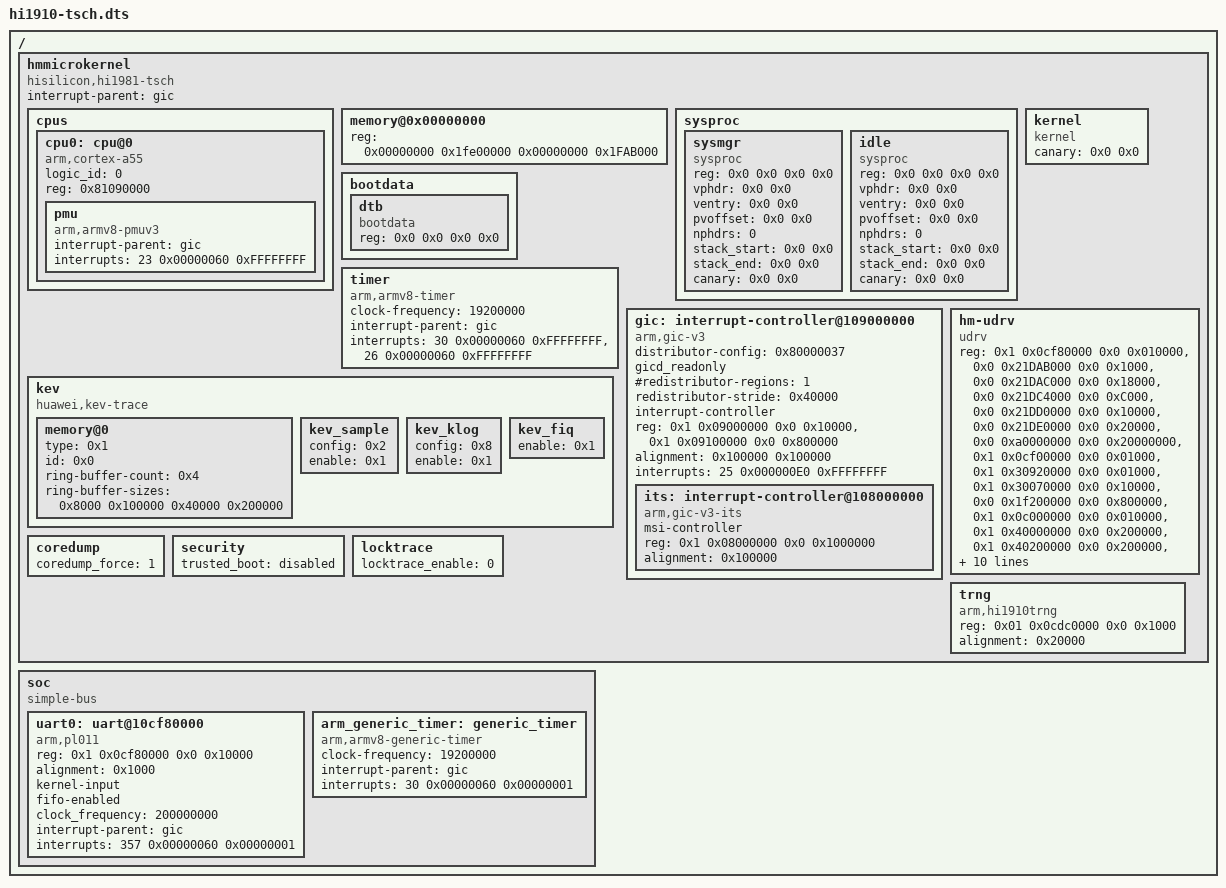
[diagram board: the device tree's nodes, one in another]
/dts-v1/;
/ { #address-cells = <2>; #size-cells = <2>; hmmicrokernel {
	compatible = "hisilicon,hi1981-tsch";
	interrupt-parent = <&gic>;
	#address-cells = <2>;
	#size-cells = <2>;

	cpus {
		#address-cells = <1>;
		#size-cells = <0>;
		cpu0: cpu@0 {
			compatible = "arm,cortex-a55", "arm,armv8";
			device_type = "cpu";
			logic_id = <0>;
			reg = <0x81090000>;
			pmu {
				compatible = "arm,armv8-pmuv3";
				interrupt-parent = <&gic>;
				/* PPI 23: PMUIRQ, level triggered, hwprio:0x60 */
				interrupts = <23 0x00000060 0xFFFFFFFF>;
			};

		};
	};

	memory@0x00000000 {
		device_type = "memory";
		reg = <0x00000000 0x1fe00000 0x00000000 0x1FAB000>;
	};

	sysproc {
		#address-cells = <2>;
		#size-cells = <2>;
		sysmgr {
			compatible = "sysproc", "sysmgr";
			/* filled by bootloader */
			reg      = <0x0 0x0 0x0 0x0>;
			vphdr    = <0x0 0x0>;
			ventry   = <0x0 0x0>;
			pvoffset = <0x0 0x0>;
			nphdrs   = <0>;
			stack_start = <0x0 0x0>;
			stack_end = <0x0 0x0>;
			canary = <0x0 0x0>;
		};

		idle {
			compatible = "sysproc", "idle";
			/* filled by bootloader */
			reg      = <0x0 0x0 0x0 0x0>;
			vphdr    = <0x0 0x0>;
			ventry   = <0x0 0x0>;
			pvoffset = <0x0 0x0>;
			nphdrs   = <0>;
			stack_start = <0x0 0x0>;
			stack_end = <0x0 0x0>;
			canary = <0x0 0x0>;
		};
	};

	kernel {
		compatible = "kernel";
		/* filled by bootloader */
		canary = <0x0 0x0>;
	};

	bootdata {
		#address-cells = <2>;
		#size-cells = <2>;
		dtb {
			compatible = "bootdata", "dtb";
			/* filled by bootloader */
			reg = <0x0 0x0 0x0 0x0>;
		};
	};

	timer {
		compatible = "arm,armv8-timer";
		clock-frequency = <19200000>;

		/* interrupt settings */
		interrupt-parent = <&gic>;

		/* PPI 30: Non-secure physical timer
		 * level triggered, hwprio:0x60 */
		interrupts = <30 0x00000060 0xFFFFFFFF>,
			     <26 0x00000060 0xFFFFFFFF>;
	};

	/* See Documentation/dts-gic.md for interrupts and distributor_config */
	gic: interrupt-controller@109000000 {
		compatible = "arm,gic-v3";

		#address-cells = <2>;
		#size-cells = <2>;

		/* Enable group 0, Group1NS, Group1S, ARE_NS, ARE_S,
		 * Split EOI and Deactive Mode */
		distributor-config = <0x80000037>;

		gicd_readonly;

		#interrupt-cells = <3>;
		#redistributor-regions = <1>;
		redistributor-stride = <0x40000>;
		interrupt-controller;

		reg =	<0x1 0x09000000 0x0 0x10000>,	/* GICD */
			<0x1 0x09100000 0x0 0x800000>;	/* GICR */
		alignment = <0x100000 0x100000>;

		interrupts = <25 0x000000E0 0xFFFFFFFF>;

		/* We haven't support this */
		its: interrupt-controller@108000000 {
			compatible = "arm,gic-v3-its";
			msi-controller;
			reg = <0x1 0x08000000 0x0 0x1000000>;
			alignment = <0x100000>;
			#interrupt-cells = <4>;
		};
	};

	kev {
		compatible = "huawei,kev-trace";

		/*
		 * This is just a sample configuration. The ring buffer size is
		 * intentially set to a small value to pass the CI test which
		 * calls kev_print() to print ALL kev data in a panic test.
		 */
		memory@0 {
			type = <0x1>;
			id = <0x0>;
			ring-buffer-count = <0x4>;
			/*
			 * Only ring buffer DATA sizes. Memory head and ring
			 * buffer heads are not included.
			 * ring buffer 0: 32K
			 * ring buffer 1: 1M (perf)
			 * ring buffer 2: 256K
			 * ring buffer 3: 2M (klog)
			 */
			ring-buffer-sizes = <0x8000 0x100000 0x40000 0x200000>;
		};
		kev_sample {
			config = <0x2>;
			enable = <0x1>;
		};
		kev_klog {
			config = <0x8>;
			enable = <0x1>;
		};
		kev_fiq {
			enable = <0x1>;
		};
	};

	hm-udrv {
		compatible = "udrv";
                reg = <0x1 0x0cf80000 0x0 0x010000>,
		      <0x0 0x21DAB000 0x0 0x1000>,
		      <0x0 0x21DAC000 0x0 0x18000>,
		      <0x0 0x21DC4000 0x0 0xC000>,
		      <0x0 0x21DD0000 0x0 0x10000>,
		      <0x0 0x21DE0000 0x0 0x20000>,
		      <0x0 0xa0000000 0x0 0x20000000>,
                      <0x1 0x0cf00000 0x0 0x01000>,
                      <0x1 0x30920000 0x0 0x01000>,
                      <0x1 0x30070000 0x0 0x10000>,
                      <0x0 0x1f200000 0x0 0x800000>,
                      <0x1 0x0c000000 0x0 0x010000>,
                      <0x1 0x40000000 0x0 0x200000>,
                      <0x1 0x40200000 0x0 0x200000>,
                      <0x1 0x100C0000 0x0 0x800000>,
                      <0x1 0xf0000000 0x0 0xa00000>,
                      <0x1 0x02000000 0x0 0x1000000>,
                      <0x0 0x9fe000   0x0 0x4000>,
                      <0x0 0x7620000  0x0 0x2000000>,
                      <0x0 0x21e00000 0x0 0x50000000>,
                      <0x2 0x00000000 0xF 0x00000000>,
                      <0x1 0x09000000 0x0 0x10000>,
                      <0x0 0x400000   0x0 0x100000>,
                      <0x1 0x00000000 0x0 0x8f0000>;
	};

	coredump {
		coredump_force = <1>;
	};

	security {
		trusted_boot = "disabled";
	};

	locktrace {
		locktrace_enable = <0>;
	};
	trng {
		compatible = "arm,hi1910trng";
		reg = <0x01 0x0cdc0000 0x0 0x1000>;
		alignment = <0x20000>;
	};
	};

	soc {
		compatible = "simple-bus";
		#address-cells = <2>;
		#size-cells = <2>;
		ranges;
		uart0: uart@10cf80000 {
			compatible = "arm,pl011", "arm,pl011,uart";
			reg = <0x1 0x0cf80000 0x0 0x10000>;
			alignment = <0x1000>;

			/* kernel control input */
			kernel-input;
			/* enable fifo */
			fifo-enabled;

			clock_frequency = <200000000>; /* 200MHz */
			interrupt-parent=<&gic>;
			interrupts=<357 0x00000060 0x00000001>;
		};

		arm_generic_timer: generic_timer {
			compatible = "arm,armv8-generic-timer";
			clock-frequency = <19200000>;

			/* interrupt settings */
			interrupt-parent = <&gic>;

			/*
			 * PPI 30: Non-secure physical timer
			 * level triggered, only cpu0, hwprio:0x60
			 */
			interrupts = <30 0x00000060 0x00000001>;
		};
	};
};
